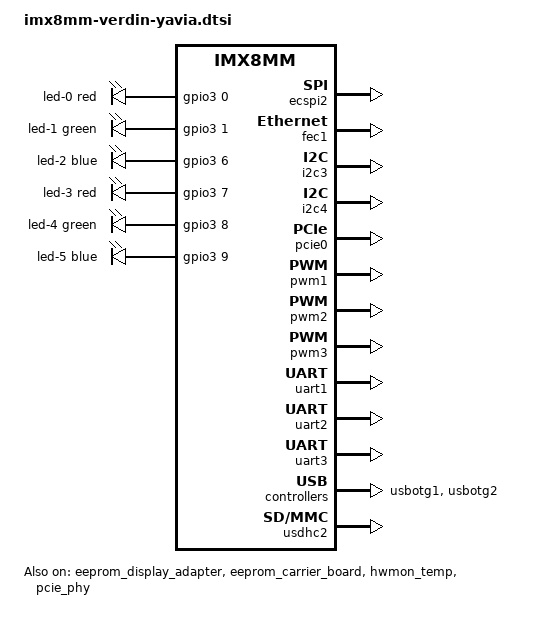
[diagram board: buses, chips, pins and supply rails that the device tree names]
#include <dt-bindings/leds/common.h>
/ {
	leds {
		compatible = "gpio-leds";
		pinctrl-names = "default";
		pinctrl-0 = <&pinctrl_leds_yavia>;
		led-0 {
			color = <LED_COLOR_ID_RED>;
			function = LED_FUNCTION_DEBUG;
			function-enumerator = <1>;
			gpios = <&gpio3 0 GPIO_ACTIVE_HIGH>;
		};
		led-1 {
			color = <LED_COLOR_ID_GREEN>;
			function = LED_FUNCTION_DEBUG;
			function-enumerator = <1>;
			gpios = <&gpio3 1 GPIO_ACTIVE_HIGH>;
		};
		led-2 {
			color = <LED_COLOR_ID_BLUE>;
			function = LED_FUNCTION_DEBUG;
			function-enumerator = <1>;
			gpios = <&gpio3 6 GPIO_ACTIVE_HIGH>;
		};
		led-3 {
			color = <LED_COLOR_ID_RED>;
			function = LED_FUNCTION_DEBUG;
			function-enumerator = <2>;
			gpios = <&gpio3 7 GPIO_ACTIVE_HIGH>;
		};
		led-4 {
			color = <LED_COLOR_ID_GREEN>;
			function = LED_FUNCTION_DEBUG;
			function-enumerator = <2>;
			gpios = <&gpio3 8 GPIO_ACTIVE_HIGH>;
		};
		led-5 {
			color = <LED_COLOR_ID_BLUE>;
			function = LED_FUNCTION_DEBUG;
			function-enumerator = <2>;
			gpios = <&gpio3 9 GPIO_ACTIVE_HIGH>;
		};
	};
};
&ecspi2 {
	status = "okay";
};
&eeprom_display_adapter {
	status = "okay";
};
&eeprom_carrier_board {
	status = "okay";
};
&fec1 {
	status = "okay";
};
&gpio3 {
	pinctrl-names = "default";
	pinctrl-0 = <&pinctrl_gpios_ext_yavia>;
};
&hwmon_temp {
	status = "okay";
};
&i2c3 {
	status = "okay";
};
&i2c4 {
	status = "okay";
};
&pcie0 {
	status = "okay";
};
&pcie_phy {
	status = "okay";
};
&pwm1 {
	status = "okay";
};
&pwm2 {
	status = "okay";
};
&pwm3 {
	status = "okay";
};
&uart1 {
	status = "okay";
};
&uart2 {
	status = "okay";
};
&uart3 {
	status = "okay";
};
&usbotg1 {
	status = "okay";
};
&usbotg2 {
	status = "okay";
};
&usdhc2 {
	status = "okay";
};
&iomuxc {
	pinctrl_leds_yavia: ledsyaviagrp {
		fsl,pins = <
			MX8MM_IOMUXC_NAND_ALE_GPIO3_IO0		0x106	 
			MX8MM_IOMUXC_NAND_CE0_B_GPIO3_IO1	0x106	 
			MX8MM_IOMUXC_NAND_DATA00_GPIO3_IO6	0x106	 
			MX8MM_IOMUXC_NAND_DATA01_GPIO3_IO7	0x106	 
			MX8MM_IOMUXC_NAND_DATA02_GPIO3_IO8	0x106	 
			MX8MM_IOMUXC_NAND_DATA03_GPIO3_IO9	0x106	 
		>;
	};
	pinctrl_gpios_ext_yavia: gpiosextyaviagrp {
		fsl,pins = <
			MX8MM_IOMUXC_NAND_CE1_B_GPIO3_IO2	0x106	 
			MX8MM_IOMUXC_NAND_DQS_GPIO3_IO14	0x106	 
		>;
	};
};
